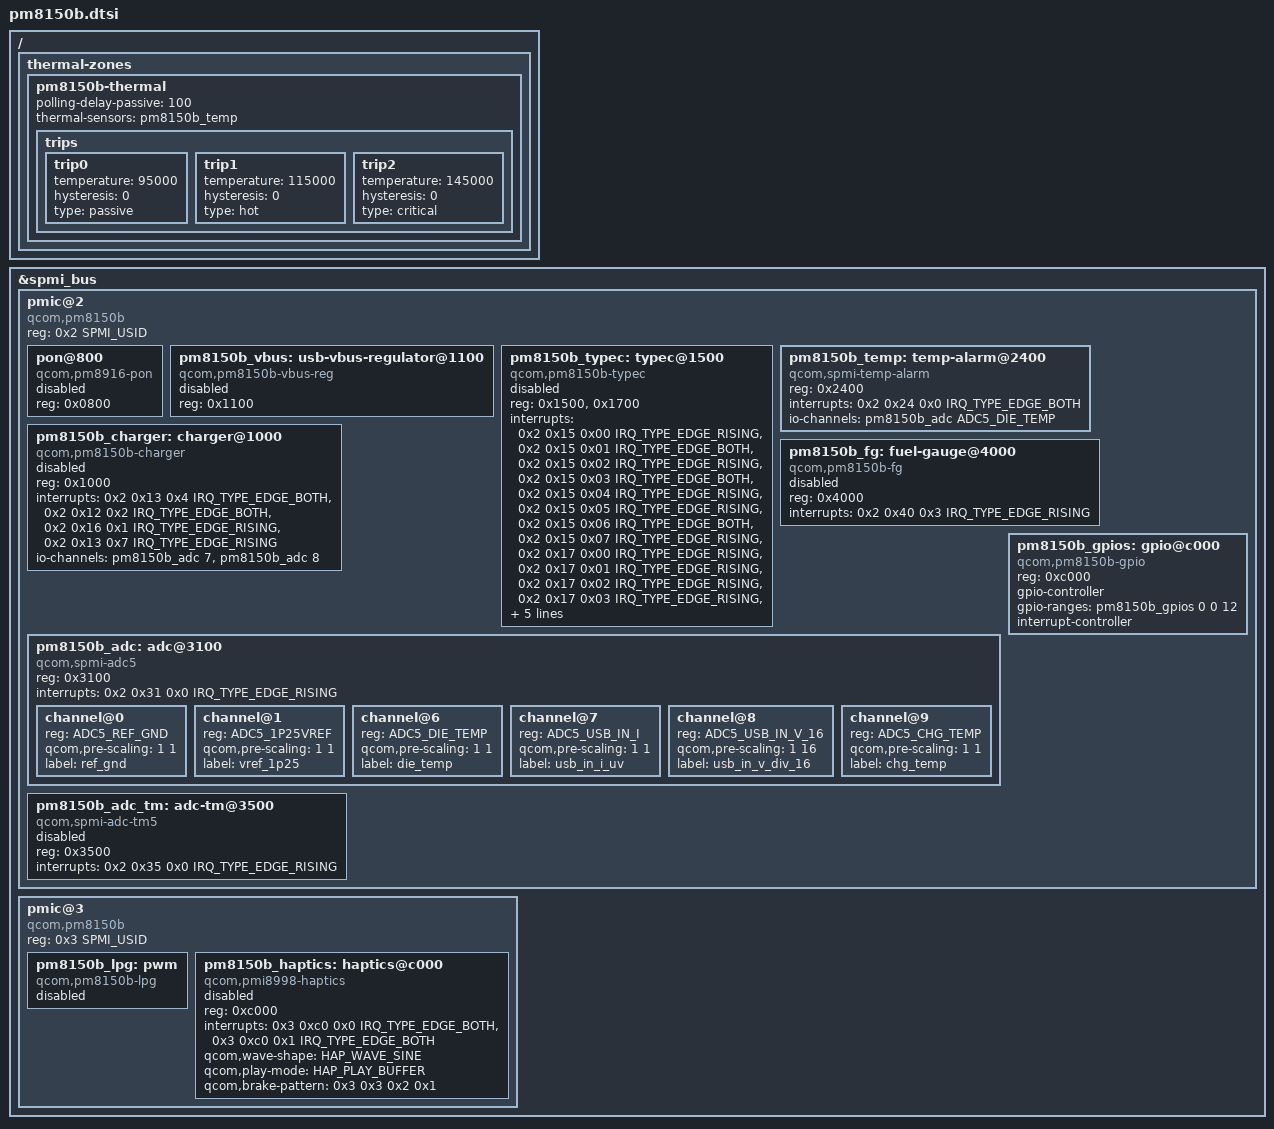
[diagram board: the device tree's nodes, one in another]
// SPDX-License-Identifier: BSD-3-Clause
/*
 * Copyright (c) 2017-2019, The Linux Foundation. All rights reserved.
 * Copyright (c) 2019, Linaro Limited
 */

#include <dt-bindings/iio/qcom,spmi-vadc.h>
#include <dt-bindings/input/qcom,spmi-haptics.h>
#include <dt-bindings/interrupt-controller/irq.h>
#include <dt-bindings/spmi/spmi.h>

/ {
	thermal-zones {
		pm8150b-thermal {
			polling-delay-passive = <100>;

			thermal-sensors = <&pm8150b_temp>;

			trips {
				trip0 {
					temperature = <95000>;
					hysteresis = <0>;
					type = "passive";
				};

				trip1 {
					temperature = <115000>;
					hysteresis = <0>;
					type = "hot";
				};

				trip2 {
					temperature = <145000>;
					hysteresis = <0>;
					type = "critical";
				};
			};
		};
	};
};

&spmi_bus {
	pmic@2 {
		compatible = "qcom,pm8150b", "qcom,spmi-pmic";
		reg = <0x2 SPMI_USID>;
		#address-cells = <1>;
		#size-cells = <0>;

		pon@800 {
			compatible = "qcom,pm8916-pon";
			reg = <0x0800>;

			status = "disabled";
		};

		pm8150b_vbus: usb-vbus-regulator@1100 {
			compatible = "qcom,pm8150b-vbus-reg";
			status = "disabled";
			reg = <0x1100>;
		};

		pm8150b_typec: typec@1500 {
			compatible = "qcom,pm8150b-typec";
			status = "disabled";
			reg = <0x1500>,
			      <0x1700>;
			interrupts = <0x2 0x15 0x00 IRQ_TYPE_EDGE_RISING>,
				     <0x2 0x15 0x01 IRQ_TYPE_EDGE_BOTH>,
				     <0x2 0x15 0x02 IRQ_TYPE_EDGE_RISING>,
				     <0x2 0x15 0x03 IRQ_TYPE_EDGE_BOTH>,
				     <0x2 0x15 0x04 IRQ_TYPE_EDGE_RISING>,
				     <0x2 0x15 0x05 IRQ_TYPE_EDGE_RISING>,
				     <0x2 0x15 0x06 IRQ_TYPE_EDGE_BOTH>,
				     <0x2 0x15 0x07 IRQ_TYPE_EDGE_RISING>,
				     <0x2 0x17 0x00 IRQ_TYPE_EDGE_RISING>,
				     <0x2 0x17 0x01 IRQ_TYPE_EDGE_RISING>,
				     <0x2 0x17 0x02 IRQ_TYPE_EDGE_RISING>,
				     <0x2 0x17 0x03 IRQ_TYPE_EDGE_RISING>,
				     <0x2 0x17 0x04 IRQ_TYPE_EDGE_RISING>,
				     <0x2 0x17 0x05 IRQ_TYPE_EDGE_RISING>,
				     <0x2 0x17 0x06 IRQ_TYPE_EDGE_RISING>,
				     <0x2 0x17 0x07 IRQ_TYPE_EDGE_RISING>;
			interrupt-names = "or-rid-detect-change",
					  "vpd-detect",
					  "cc-state-change",
					  "vconn-oc",
					  "vbus-change",
					  "attach-detach",
					  "legacy-cable-detect",
					  "try-snk-src-detect",
					  "sig-tx",
					  "sig-rx",
					  "msg-tx",
					  "msg-rx",
					  "msg-tx-failed",
					  "msg-tx-discarded",
					  "msg-rx-discarded",
					  "fr-swap";
			vdd-vbus-supply = <&pm8150b_vbus>;
		};

		pm8150b_temp: temp-alarm@2400 {
			compatible = "qcom,spmi-temp-alarm";
			reg = <0x2400>;
			interrupts = <0x2 0x24 0x0 IRQ_TYPE_EDGE_BOTH>;
			io-channels = <&pm8150b_adc ADC5_DIE_TEMP>;
			io-channel-names = "thermal";
			#thermal-sensor-cells = <0>;
		};

		pm8150b_charger: charger@1000 {
			compatible = "qcom,pm8150b-charger";
			reg = <0x1000>;

			interrupts = <0x2 0x13 0x4 IRQ_TYPE_EDGE_BOTH>,
				     <0x2 0x12 0x2 IRQ_TYPE_EDGE_BOTH>,
				     <0x2 0x16 0x1 IRQ_TYPE_EDGE_RISING>,
				     <0x2 0x13 0x7 IRQ_TYPE_EDGE_RISING>;
			interrupt-names = "usbin-plugin",
					  "bat-ov",
					  "wdog-bark",
					  "usbin-icl-change";

			io-channels = <&pm8150b_adc 7>,
				      <&pm8150b_adc 8>;
			io-channel-names = "usb_in_i_uv", "usb_in_v_div_16";

			status = "disabled";
		};

		pm8150b_fg: fuel-gauge@4000 {
			compatible = "qcom,pm8150b-fg";
			reg = <0x4000>;
			interrupts = <0x2 0x40 0x3 IRQ_TYPE_EDGE_RISING>;
			interrupt-names = "soc-delta";
			status = "disabled";
		};

		pm8150b_adc: adc@3100 {
			compatible = "qcom,spmi-adc5";
			reg = <0x3100>;
			#address-cells = <1>;
			#size-cells = <0>;
			#io-channel-cells = <1>;
			interrupts = <0x2 0x31 0x0 IRQ_TYPE_EDGE_RISING>;

			channel@0 {
				reg = <ADC5_REF_GND>;
				qcom,pre-scaling = <1 1>;
				label = "ref_gnd";
			};

			channel@1 {
				reg = <ADC5_1P25VREF>;
				qcom,pre-scaling = <1 1>;
				label = "vref_1p25";
			};

			channel@6 {
				reg = <ADC5_DIE_TEMP>;
				qcom,pre-scaling = <1 1>;
				label = "die_temp";
			};

			channel@7 {
				reg = <ADC5_USB_IN_I>;
				qcom,pre-scaling = <1 1>;
				label = "usb_in_i_uv";
			};

			channel@8 {
				reg = <ADC5_USB_IN_V_16>;
				qcom,pre-scaling = <1 16>;
				label = "usb_in_v_div_16";
			};

			channel@9 {
				reg = <ADC5_CHG_TEMP>;
				qcom,pre-scaling = <1 1>;
				label = "chg_temp";
			};
		};

		pm8150b_adc_tm: adc-tm@3500 {
			compatible = "qcom,spmi-adc-tm5";
			reg = <0x3500>;
			interrupts = <0x2 0x35 0x0 IRQ_TYPE_EDGE_RISING>;
			#thermal-sensor-cells = <1>;
			#address-cells = <1>;
			#size-cells = <0>;
			status = "disabled";
		};

		pm8150b_gpios: gpio@c000 {
			compatible = "qcom,pm8150b-gpio", "qcom,spmi-gpio";
			reg = <0xc000>;
			gpio-controller;
			gpio-ranges = <&pm8150b_gpios 0 0 12>;
			#gpio-cells = <2>;
			interrupt-controller;
			#interrupt-cells = <2>;
		};
	};

	pmic@3 {
		compatible = "qcom,pm8150b", "qcom,spmi-pmic";
		reg = <0x3 SPMI_USID>;
		#address-cells = <1>;
		#size-cells = <0>;

		pm8150b_lpg: pwm {
			compatible = "qcom,pm8150b-lpg";

			#address-cells = <1>;
			#size-cells = <0>;
			#pwm-cells = <2>;

			status = "disabled";
		};

		pm8150b_haptics: haptics@c000 {
			compatible = "qcom,pmi8998-haptics", "qcom,spmi-haptics";
			reg = <0xc000>;

			interrupts = <0x3 0xc0 0x0 IRQ_TYPE_EDGE_BOTH>,
				     <0x3 0xc0 0x1 IRQ_TYPE_EDGE_BOTH>;
			interrupt-names = "short", "play";

			qcom,wave-shape = <HAP_WAVE_SINE>;
			qcom,play-mode = <HAP_PLAY_BUFFER>;
			qcom,brake-pattern = <0x3 0x3 0x2 0x1>;

			status = "disabled";
		};
	};
};
